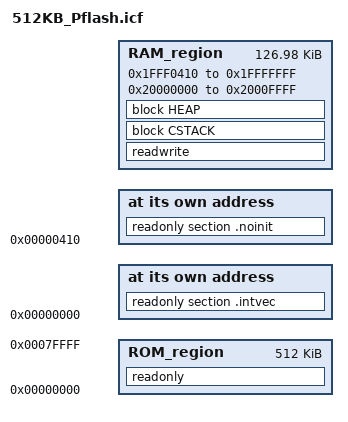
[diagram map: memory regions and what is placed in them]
/*###ICF### Section handled by ICF editor, don't touch! ****/
/*-Editor annotation file-*/
/* IcfEditorFile="$TOOLKIT_DIR$\config\ide\IcfEditor\cortex_v1_0.xml" */
/*-Specials-*/
define symbol __ICFEDIT_intvec_start__ = 0x00000000;
/*-Memory Regions-*/
define symbol __ICFEDIT_region_ROM_start__ = 0x00000000;
define symbol __ICFEDIT_region_ROM_end__   = 0x0007ffff;
define symbol __ICFEDIT_region_RAM_start__ = 0x1fff0410;
define symbol __ICFEDIT_region_RAM_end__   = 0x1fffffff;
/*-Sizes-*/
define symbol __ICFEDIT_size_cstack__ = 0x1000;
define symbol __ICFEDIT_size_heap__   = 0x200;
/**** End of ICF editor section. ###ICF###*/

define symbol __region_RAM2_start__ = 0x20000000;
define symbol __region_RAM2_end__ = 0x2000ffff;

define exported symbol __VECTOR_TABLE = 0x00000000;
define exported symbol __VECTOR_RAM = 0x1fff0000;

define exported symbol __BOOT_STACK_ADDRESS = __region_RAM2_end__ - 7;	//0x2000FFF8;

define symbol __code_start__ = 0x00000410;

define memory mem with size = 4G;
define region ROM_region   = mem:[from __ICFEDIT_region_ROM_start__   to __ICFEDIT_region_ROM_end__];
define region RAM_region   = mem:[from __ICFEDIT_region_RAM_start__   to __ICFEDIT_region_RAM_end__] | mem:[from __region_RAM2_start__ to __region_RAM2_end__];

define block CSTACK    with alignment = 8, size = __ICFEDIT_size_cstack__   { };
define block HEAP      with alignment = 8, size = __ICFEDIT_size_heap__     { };

initialize by copy { readwrite };
do not initialize  { section .noinit };

place at address mem:__ICFEDIT_intvec_start__ { readonly section .intvec };
place at address mem:__code_start__ { readonly section .noinit };

place in ROM_region   { readonly };

place in RAM_region   { readwrite, block CSTACK, block HEAP };
